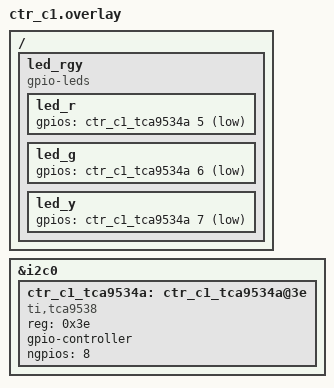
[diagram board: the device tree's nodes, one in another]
/*
 * Copyright (c) 2023 HARDWARIO a.s.
 *
 * SPDX-License-Identifier: LicenseRef-HARDWARIO-5-Clause
 */

/ {
	led_rgy {
		compatible = "gpio-leds";

		led_r: led_r {
			gpios = <&ctr_c1_tca9534a 5 GPIO_ACTIVE_LOW>;
		};

		led_g: led_g {
			gpios = <&ctr_c1_tca9534a 6 GPIO_ACTIVE_LOW>;
		};

		led_y: led_y {
			gpios = <&ctr_c1_tca9534a 7 GPIO_ACTIVE_LOW>;
		};
	};
};

&i2c0 {
	ctr_c1_tca9534a: ctr_c1_tca9534a@3e {
		compatible = "ti,tca9538";
		status = "okay";
		reg = <0x3e>;
		#gpio-cells = <2>;
		gpio-controller;
		ngpios = <8>;
	};
};
